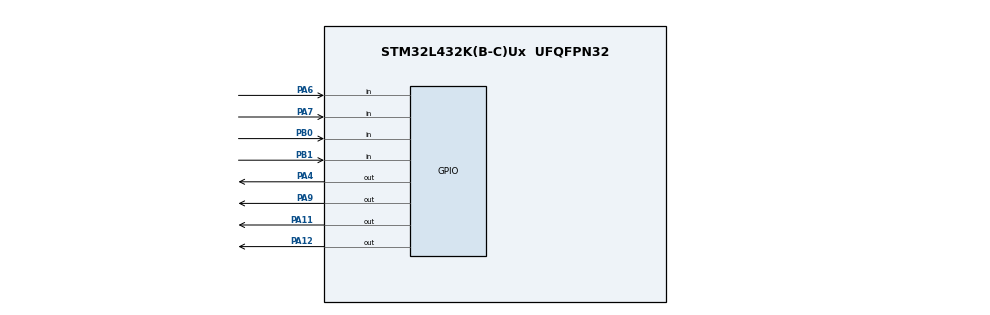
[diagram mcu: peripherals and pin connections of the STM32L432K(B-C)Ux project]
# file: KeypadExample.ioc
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Mcu.Family=STM32L4
Mcu.Name=STM32L432K(B-C)Ux
Mcu.Package=UFQFPN32
NVIC.PriorityGroup=NVIC_PRIORITYGROUP_4
PA11.Signal=GPIO_Output
PA12.Signal=GPIO_Output
PA4.Signal=GPIO_Output
PA6.Signal=GPIO_Input
PA7.Signal=GPIO_Input
PA9.Signal=GPIO_Output
PB0.Signal=GPIO_Input
PB1.Signal=GPIO_Input
ProjectManager.HeapSize=0x200
ProjectManager.StackSize=0x400
ProjectManager.TargetToolchain=STM32CubeIDE
RCC.HSE_VALUE=8000000
RCC.HSI48_VALUE=48000000
RCC.HSI_VALUE=16000000
RCC.LSE_VALUE=32768
RCC.MSI_VALUE=4000000
RCC.VCOOutputFreq_Value=32000000
board=custom

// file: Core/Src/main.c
/* USER CODE BEGIN Header */
/**
  ******************************************************************************
  * @file           : main.c
  * @brief          : Main program body
  ******************************************************************************
  * @attention
  *
  * <h2><center>&copy; Copyright (c) 2022 STMicroelectronics.
  * All rights reserved.</center></h2>
  *
  * This software component is licensed by ST under BSD 3-Clause license,
  * the "License"; You may not use this file except in compliance with the
  * License. You may obtain a copy of the License at:
  *                        opensource.org/licenses/BSD-3-Clause
  *
  ******************************************************************************
  */
/* USER CODE END Header */
#include "main.h"
#include "../../ECUAL/KEYPAD/KEYPAD.h"
#include "../../ECUAL/KEYPAD/KEYPAD.c"

/* USER CODE BEGIN Includes */

#define LED_BLUE    0
#define LED_YELLOW  1

#define KEY_1       0
#define KEY_2       1

uint8_t gu8_KeyStatesArr[KEYS] = {0};
uint8_t SysTicks = 0;

unsigned state=0;

/* USER CODE END Includes */

void SystemClock_Config(void);
static void MX_GPIO_Init(void);

/* USER CODE BEGIN PFP */
void SysTick_CallBack(void)
{
    SysTicks++;
    if(SysTicks == 5) // Each 5msec
    {
    KEYPAD_Scan(0);
    SysTicks = 0;
    }
}
/* USER CODE END PFP */

int main(void)
{

  /* MCU Configuration--------------------------------------------------------*/

  /* Reset of all peripherals, Initializes the Flash interface and the Systick. */
  HAL_Init();

  /* Configure the system clock */
  SystemClock_Config();

  /* Initialize all configured peripherals */
  MX_GPIO_Init();

  /* Infinite loop */
  /* USER CODE BEGIN WHILE */
  while (1)
  {
	  /* USER CODE BEGIN 3 */

	  //KEYPAD_Scan(16);
    /* USER CODE END WHILE */
	  if(gu8_KeyStatesArr[KEY_1] == KEY_PRESSED)
	          {
	              state=1;
	          }
	  else if(gu8_KeyStatesArr[KEY_2] == KEY_PRESSED)
	          {
	        	  state=2;
	          }
	  else if(gu8_KeyStatesArr[KEY_3] == KEY_PRESSED)
	          {
	        	  state=3;
	          }
	  else if(gu8_KeyStatesArr[KEY_4] == KEY_PRESSED)
	          {
	        	  state=4;
	          }
	  else if(gu8_KeyStatesArr[KEY_5] == KEY_PRESSED)
	          {
	        	  state=5;
	          }
	  else if(gu8_KeyStatesArr[KEY_6] == KEY_PRESSED)
	          {
	        	  state=6;
	          }
	  else if(gu8_KeyStatesArr[KEY_7] == KEY_PRESSED)
	          {
	        	  state=7;
	          }
	  else if(gu8_KeyStatesArr[KEY_8] == KEY_PRESSED)
	          {
	        	  state=8;
	          }
	  else if(gu8_KeyStatesArr[KEY_9] == KEY_PRESSED)
	          {
	        	  state=9;
	          }
	          else
	          {
	        	  state=0;
	          }
    }

  /* USER CODE END 3 */
}

void SystemClock_Config(void)
{
  RCC_OscInitTypeDef RCC_OscInitStruct = {0};
  RCC_ClkInitTypeDef RCC_ClkInitStruct = {0};

  /** Initializes the RCC Oscillators according to the specified parameters
  * in the RCC_OscInitTypeDef structure.
  */
  RCC_OscInitStruct.OscillatorType = RCC_OSCILLATORTYPE_MSI;
  RCC_OscInitStruct.MSIState = RCC_MSI_ON;
  RCC_OscInitStruct.MSICalibrationValue = 0;
  RCC_OscInitStruct.MSIClockRange = RCC_MSIRANGE_6;
  RCC_OscInitStruct.PLL.PLLState = RCC_PLL_NONE;
  if (HAL_RCC_OscConfig(&RCC_OscInitStruct) != HAL_OK)
  {
    Error_Handler();
  }
  /** Initializes the CPU, AHB and APB buses clocks
  */
  RCC_ClkInitStruct.ClockType = RCC_CLOCKTYPE_HCLK|RCC_CLOCKTYPE_SYSCLK
                              |RCC_CLOCKTYPE_PCLK1|RCC_CLOCKTYPE_PCLK2;
  RCC_ClkInitStruct.SYSCLKSource = RCC_SYSCLKSOURCE_MSI;
  RCC_ClkInitStruct.AHBCLKDivider = RCC_SYSCLK_DIV1;
  RCC_ClkInitStruct.APB1CLKDivider = RCC_HCLK_DIV1;
  RCC_ClkInitStruct.APB2CLKDivider = RCC_HCLK_DIV1;

  if (HAL_RCC_ClockConfig(&RCC_ClkInitStruct, FLASH_LATENCY_0) != HAL_OK)
  {
    Error_Handler();
  }
  /** Configure the main internal regulator output voltage
  */
  if (HAL_PWREx_ControlVoltageScaling(PWR_REGULATOR_VOLTAGE_SCALE1) != HAL_OK)
  {
    Error_Handler();
  }
}

static void MX_GPIO_Init(void)
{
  GPIO_InitTypeDef GPIO_InitStruct = {0};

  /* GPIO Ports Clock Enable */
  __HAL_RCC_GPIOA_CLK_ENABLE();
  __HAL_RCC_GPIOB_CLK_ENABLE();

  /*Configure GPIO pin Output Level */
  HAL_GPIO_WritePin(GPIOA, GPIO_PIN_4|GPIO_PIN_9|GPIO_PIN_11|GPIO_PIN_12, GPIO_PIN_RESET);

  /*Configure GPIO pins : PA4 PA9 PA11 PA12 */
  GPIO_InitStruct.Pin = GPIO_PIN_4|GPIO_PIN_9|GPIO_PIN_11|GPIO_PIN_12;
  GPIO_InitStruct.Mode = GPIO_MODE_OUTPUT_PP;
  GPIO_InitStruct.Pull = GPIO_NOPULL;
  GPIO_InitStruct.Speed = GPIO_SPEED_FREQ_LOW;
  HAL_GPIO_Init(GPIOA, &GPIO_InitStruct);

  /*Configure GPIO pins : PA6 PA7 */
  GPIO_InitStruct.Pin = GPIO_PIN_6|GPIO_PIN_7;
  GPIO_InitStruct.Mode = GPIO_MODE_INPUT;
  GPIO_InitStruct.Pull = GPIO_PULLUP;
  HAL_GPIO_Init(GPIOA, &GPIO_InitStruct);

  /*Configure GPIO pins : PB0 PB1 */
  GPIO_InitStruct.Pin = GPIO_PIN_0|GPIO_PIN_1;
  GPIO_InitStruct.Mode = GPIO_MODE_INPUT;
  GPIO_InitStruct.Pull = GPIO_PULLUP;
  HAL_GPIO_Init(GPIOB, &GPIO_InitStruct);

}

void Error_Handler(void)
{
  __disable_irq();
  while (1)
  {
  }
}

/************************ (C) COPYRIGHT STMicroelectronics *****END OF FILE****/
